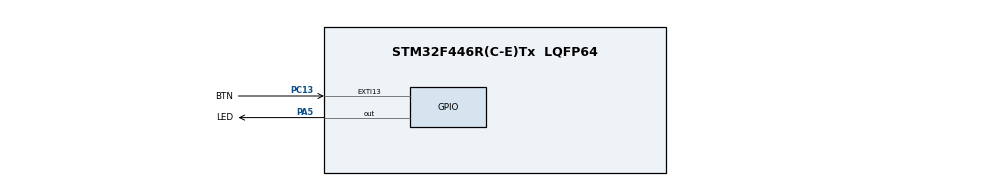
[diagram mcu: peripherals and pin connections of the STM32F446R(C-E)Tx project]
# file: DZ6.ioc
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Mcu.Family=STM32F4
Mcu.Name=STM32F446R(C-E)Tx
Mcu.Package=LQFP64
NVIC.EXTI15_10_IRQn=true\:0\:0\:false\:false\:true\:true\:true\:true
NVIC.PriorityGroup=NVIC_PRIORITYGROUP_4
PA13.Mode=Serial_Wire
PA13.Signal=SYS_JTMS-SWDIO
PA14.Mode=Serial_Wire
PA14.Signal=SYS_JTCK-SWCLK
PA5.GPIO_Label=LED
PA5.Signal=GPIO_Output
PC13.GPIO_Label=BTN
PC13.GPIO_ModeDefaultEXTI=GPIO_MODE_IT_FALLING
PC13.Signal=GPXTI13
ProjectManager.HeapSize=0x200
ProjectManager.StackSize=0x400
ProjectManager.TargetToolchain=STM32CubeIDE
RCC.CortexFreq_Value=16000000
RCC.USBFreq_Value=96000000
RCC.VCOOutputFreq_Value=192000000
TIM1.Period=7499
TIM1.Prescaler=15999
TIM1.TIM_MasterOutputTrigger=TIM_TRGO_UPDATE
VP_TIM1_VS_ClockSourceINT.Mode=Internal
board=custom

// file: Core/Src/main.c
/* USER CODE BEGIN Header */
/**
  ******************************************************************************
  * @file           : main.c
  * @brief          : Main program body
  ******************************************************************************
  * @attention
  *
  * Copyright (c) 2026 STMicroelectronics.
  * All rights reserved.
  *
  * This software is licensed under terms that can be found in the LICENSE file
  * in the root directory of this software component.
  * If no LICENSE file comes with this software, it is provided AS-IS.
  *
  ******************************************************************************
  */
/* USER CODE END Header */
#include "main.h"

TIM_HandleTypeDef htim1;

void SystemClock_Config(void);
static void MX_GPIO_Init(void);
static void MX_TIM1_Init(void);

int main(void)
{

  /* MCU Configuration--------------------------------------------------------*/

  /* Reset of all peripherals, Initializes the Flash interface and the Systick. */
  HAL_Init();

  /* Configure the system clock */
  SystemClock_Config();

  /* Initialize all configured peripherals */
  MX_GPIO_Init();
  MX_TIM1_Init();
  /* USER CODE BEGIN 2 */

  HAL_TIM_Base_Start_IT(&htim1);

  HAL_SuspendTick();

  HAL_NVIC_DisableIRQ(EXTI15_10_IRQn);
  HAL_NVIC_DisableIRQ(TIM1_UP_TIM10_IRQn);

  SCB->SCR |= SCB_SCR_SEVONPEND_Msk;
  HAL_PWR_EnterSLEEPMode(PWR_MAINREGULATOR_ON, PWR_SLEEPENTRY_WFE);

  HAL_ResumeTick();
  HAL_GPIO_WritePin(LED_GPIO_Port, LED_Pin, GPIO_PIN_SET);
  /* USER CODE END 2 */

  /* Infinite loop */
  while (1)
  {

  }
}

void SystemClock_Config(void)
{
  RCC_OscInitTypeDef RCC_OscInitStruct = {0};
  RCC_ClkInitTypeDef RCC_ClkInitStruct = {0};

  /** Configure the main internal regulator output voltage
  */
  __HAL_RCC_PWR_CLK_ENABLE();
  __HAL_PWR_VOLTAGESCALING_CONFIG(PWR_REGULATOR_VOLTAGE_SCALE3);

  /** Initializes the RCC Oscillators according to the specified parameters
  * in the RCC_OscInitTypeDef structure.
  */
  RCC_OscInitStruct.OscillatorType = RCC_OSCILLATORTYPE_HSI;
  RCC_OscInitStruct.HSIState = RCC_HSI_ON;
  RCC_OscInitStruct.HSICalibrationValue = RCC_HSICALIBRATION_DEFAULT;
  RCC_OscInitStruct.PLL.PLLState = RCC_PLL_NONE;
  if (HAL_RCC_OscConfig(&RCC_OscInitStruct) != HAL_OK)
  {
    Error_Handler();
  }

  /** Initializes the CPU, AHB and APB buses clocks
  */
  RCC_ClkInitStruct.ClockType = RCC_CLOCKTYPE_HCLK|RCC_CLOCKTYPE_SYSCLK
                              |RCC_CLOCKTYPE_PCLK1|RCC_CLOCKTYPE_PCLK2;
  RCC_ClkInitStruct.SYSCLKSource = RCC_SYSCLKSOURCE_HSI;
  RCC_ClkInitStruct.AHBCLKDivider = RCC_SYSCLK_DIV1;
  RCC_ClkInitStruct.APB1CLKDivider = RCC_HCLK_DIV1;
  RCC_ClkInitStruct.APB2CLKDivider = RCC_HCLK_DIV1;

  if (HAL_RCC_ClockConfig(&RCC_ClkInitStruct, FLASH_LATENCY_0) != HAL_OK)
  {
    Error_Handler();
  }
}

static void MX_TIM1_Init(void)
{

  TIM_ClockConfigTypeDef sClockSourceConfig = {0};
  TIM_MasterConfigTypeDef sMasterConfig = {0};

  htim1.Instance = TIM1;
  htim1.Init.Prescaler = 15999;
  htim1.Init.CounterMode = TIM_COUNTERMODE_UP;
  htim1.Init.Period = 7499;
  htim1.Init.ClockDivision = TIM_CLOCKDIVISION_DIV1;
  htim1.Init.RepetitionCounter = 0;
  htim1.Init.AutoReloadPreload = TIM_AUTORELOAD_PRELOAD_DISABLE;
  if (HAL_TIM_Base_Init(&htim1) != HAL_OK)
  {
    Error_Handler();
  }
  sClockSourceConfig.ClockSource = TIM_CLOCKSOURCE_INTERNAL;
  if (HAL_TIM_ConfigClockSource(&htim1, &sClockSourceConfig) != HAL_OK)
  {
    Error_Handler();
  }
  sMasterConfig.MasterOutputTrigger = TIM_TRGO_UPDATE;
  sMasterConfig.MasterSlaveMode = TIM_MASTERSLAVEMODE_DISABLE;
  if (HAL_TIMEx_MasterConfigSynchronization(&htim1, &sMasterConfig) != HAL_OK)
  {
    Error_Handler();
  }

}

static void MX_GPIO_Init(void)
{
  GPIO_InitTypeDef GPIO_InitStruct = {0};

  /* GPIO Ports Clock Enable */
  __HAL_RCC_GPIOC_CLK_ENABLE();
  __HAL_RCC_GPIOA_CLK_ENABLE();

  /*Configure GPIO pin Output Level */
  HAL_GPIO_WritePin(LED_GPIO_Port, LED_Pin, GPIO_PIN_RESET);

  /*Configure GPIO pin : BTN_Pin */
  GPIO_InitStruct.Pin = BTN_Pin;
  GPIO_InitStruct.Mode = GPIO_MODE_IT_FALLING;
  GPIO_InitStruct.Pull = GPIO_NOPULL;
  HAL_GPIO_Init(BTN_GPIO_Port, &GPIO_InitStruct);

  /*Configure GPIO pin : LED_Pin */
  GPIO_InitStruct.Pin = LED_Pin;
  GPIO_InitStruct.Mode = GPIO_MODE_OUTPUT_PP;
  GPIO_InitStruct.Pull = GPIO_NOPULL;
  GPIO_InitStruct.Speed = GPIO_SPEED_FREQ_LOW;
  HAL_GPIO_Init(LED_GPIO_Port, &GPIO_InitStruct);

  /* EXTI interrupt init*/
  HAL_NVIC_SetPriority(EXTI15_10_IRQn, 0, 0);
  HAL_NVIC_EnableIRQ(EXTI15_10_IRQn);

}

void Error_Handler(void)
{
  __disable_irq();
  while (1)
  {
  }
}
